# STM32F334x register map
File version: 1.1
Registers are 32-bit, read-write, reset 0x0 unless marked. A register's access mark holds for its fields unless they carry their own. Offsets are from the block's base; [hi:lo] are bit positions; {n}, {i} and the like mark numbered series.

## HRTIM_Master — High Resolution Timer: Master Timers
Base 0x40017400
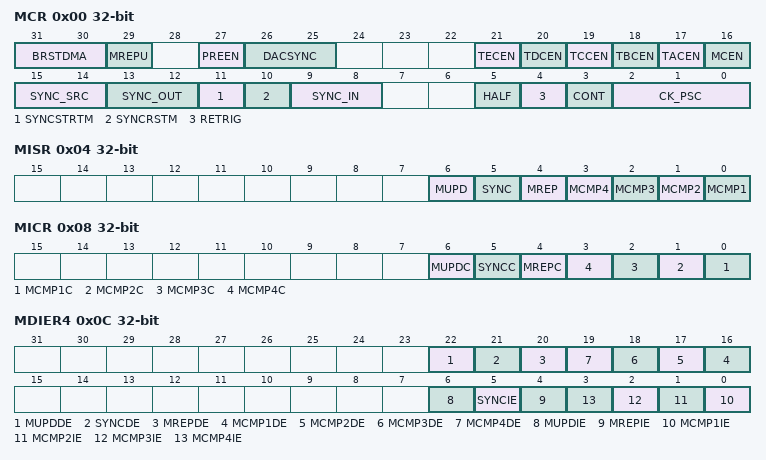
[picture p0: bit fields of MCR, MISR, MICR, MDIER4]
0x00 MCR — Master Timer Control Register
  [31:30] BRSTDMA — Burst DMA Update
  [29] MREPU — Master Timer Repetition update
  [27] PREEN — Preload enable
  [26:25] DACSYNC — AC Synchronization
  [21] TECEN — Timer E counter enable
  [20] TDCEN — Timer D counter enable
  [19] TCCEN — Timer C counter enable
  [18] TBCEN — Timer B counter enable
  [17] TACEN — Timer A counter enable
  [16] MCEN — Master Counter enable
  [15:14] SYNC_SRC — Synchronization source
  [13:12] SYNC_OUT — Synchronization output
  [11] SYNCSTRTM — Synchronization Starts Master
  [10] SYNCRSTM — Synchronization Resets Master
  [9:8] SYNC_IN — ynchronization input
  [5] HALF — Half mode enable
  [4] RETRIG — Master Re-triggerable mode
  [3] CONT — Master Continuous mode
  [2:0] CK_PSC — HRTIM Master Clock prescaler
0x04 MISR ro — Master Timer Interrupt Status Register
  [6] MUPD — Master Update Interrupt Flag
  [5] SYNC — Sync Input Interrupt Flag
  [4] MREP — Master Repetition Interrupt Flag
  [n-1] MCMP{n} (n=1..4) — Master Compare {n} Interrupt Flag
0x08 MICR wo — Master Timer Interrupt Clear Register
  [6] MUPDC — Master update Interrupt flag clear
  [5] SYNCC — Sync Input Interrupt flag clear
  [4] MREPC — Repetition Interrupt flag clear
  [n-1] MCMP{n}C (n=1..4) — Master Compare {n} Interrupt flag clear
0x0C MDIER4
  [22] MUPDDE, [21] SYNCDE, [20] MREPDE, [n+15] MCMP{n}DE (n=1..4), [6] MUPDIE, [5] SYNCIE, [4] MREPIE, [n-1] MCMP{n}IE (n=1..4)
0x10 MCNTR — Master Timer Counter Register
  [15:0] MCNT — Counter value
0x14 MPER reset 0xFFFF — Master Timer Period Register
  [15:0] MPER — Master Timer Period value
0x18 MREP — Master Timer Repetition Register
  [7:0] MREP — Master Timer Repetition counter value
0x1C MCMP1R — Master Timer Compare 1 Register
  [15:0] MCMP1 — Master Timer Compare 1 value
{0x1C+4i} MCMP{i}R (i=2..4) — Master Timer Compare {i} Register
  [15:0] MCMP{i} — Master Timer Compare {i} value

## ADC1 — Analog-to-Digital Converter
Base 0x50000000
Same registers: ADC2 0x50000100
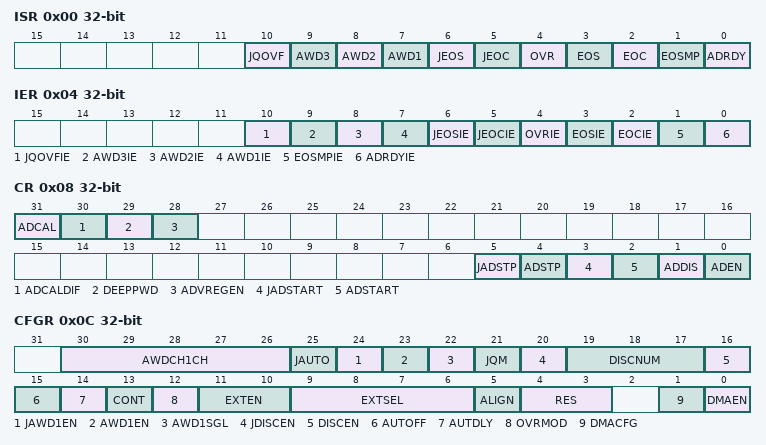
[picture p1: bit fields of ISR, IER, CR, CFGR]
0x00 ISR — interrupt and status register
  [10] JQOVF, [9] AWD3, [8] AWD2, [7] AWD1, [6] JEOS, [5] JEOC, [4] OVR, [3] EOS, [2] EOC, [1] EOSMP, [0] ADRDY
0x04 IER — interrupt enable register
  [10] JQOVFIE, [9] AWD3IE, [8] AWD2IE, [7] AWD1IE, [6] JEOSIE, [5] JEOCIE, [4] OVRIE, [3] EOSIE, [2] EOCIE, [1] EOSMPIE, [0] ADRDYIE
0x08 CR — control register
  [31] ADCAL, [30] ADCALDIF, [29] DEEPPWD, [28] ADVREGEN, [5] JADSTP, [4] ADSTP, [3] JADSTART, [2] ADSTART, [1] ADDIS, [0] ADEN
0x0C CFGR — configuration register
  [30:26] AWDCH1CH, [25] JAUTO, [24] JAWD1EN, [23] AWD1EN, [22] AWD1SGL, [21] JQM, [20] JDISCEN, [19:17] DISCNUM, [16] DISCEN, [15] AUTOFF, [14] AUTDLY, [13] CONT, [12] OVRMOD, [11:10] EXTEN, [9:6] EXTSEL, [5] ALIGN, [4:3] RES, [1] DMACFG, [0] DMAEN
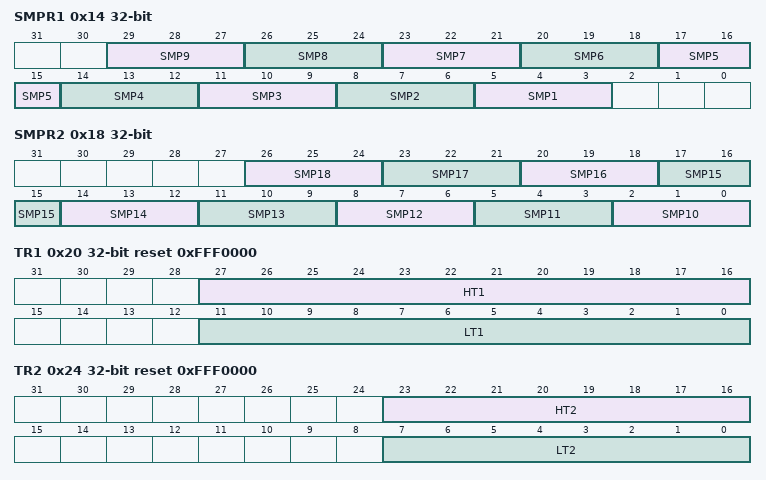
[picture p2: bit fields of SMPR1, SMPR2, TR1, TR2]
0x14 SMPR1 — sample time register 1
  [3n+2:3n] SMP{n} (n=1..9)
0x18 SMPR2 — sample time register 2
  [3n-28:3n-30] SMP{n} (n=10..18)
0x20 TR1 reset 0xFFF0000 — watchdog threshold register 1
  [27:16] HT1, [11:0] LT1
0x24 TR2 reset 0xFFF0000 — watchdog threshold register
  [23:16] HT2, [7:0] LT2
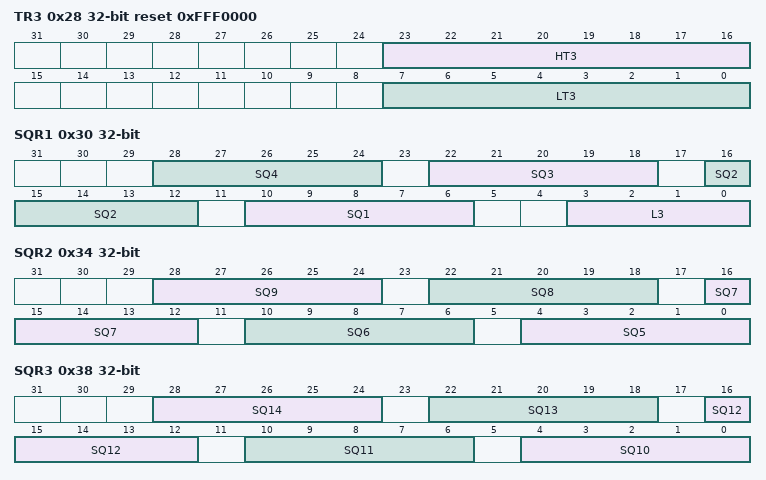
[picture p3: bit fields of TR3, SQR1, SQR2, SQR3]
0x28 TR3 reset 0xFFF0000 — watchdog threshold register 3
  [23:16] HT3, [7:0] LT3
0x30 SQR1 — regular sequence register 1
  [6n+4:6n] SQ{n} (n=1..4), [3:0] L3
0x34 SQR2 — regular sequence register 2
  [6n-26:6n-30] SQ{n} (n=5..9)
0x38 SQR3 — regular sequence register 3
  [6n-56:6n-60] SQ{n} (n=10..14)
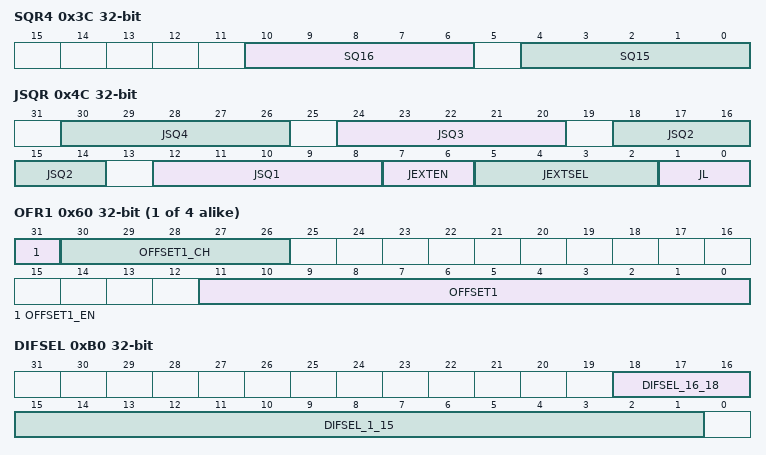
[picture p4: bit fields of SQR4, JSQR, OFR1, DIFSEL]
0x3C SQR4 — regular sequence register 4
  [10:6] SQ16, [4:0] SQ15
0x40 DR ro — regular Data Register
  [15:0] regularDATA
0x4C JSQR — injected sequence register
  [6n+6:6n+2] JSQ{n} (n=1..4), [7:6] JEXTEN, [5:2] JEXTSEL, [1:0] JL
{0x5C+4i} OFR{i} (i=1..4) — offset register {i}
  [31] OFFSET{i}_EN, [30:26] OFFSET{i}_CH, [11:0] OFFSET{i}
{0x7C+4i} JDR{i} ro (i=1..4) — injected data register {i}
  [15:0] JDATA{i}
0xA0 AWD2CR — Analog Watchdog 2 Configuration Register
  [18:1] AWD2CH
0xA4 AWD3CR — Analog Watchdog 3 Configuration Register
  [18:1] AWD3CH
0xB0 DIFSEL access per field — Differential Mode Selection Register 2
  [18:16] DIFSEL_16_18 ro — Differential mode for channels 18 to 16
  [15:1] DIFSEL_1_15 rw — Differential mode for channels 15 to 1
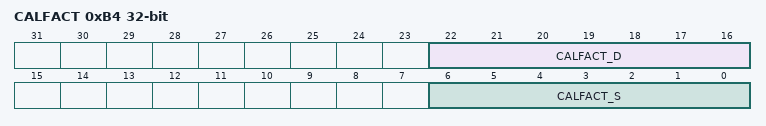
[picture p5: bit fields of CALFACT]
0xB4 CALFACT — Calibration Factors
  [22:16] CALFACT_D, [6:0] CALFACT_S

## ADC1_2 — Analog-to-Digital Converter
Base 0x50000300
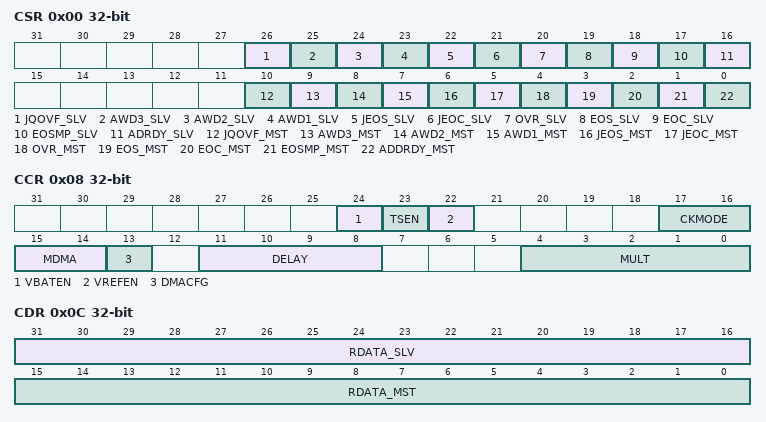
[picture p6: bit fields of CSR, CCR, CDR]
0x00 CSR ro — ADC Common status register
  [26] JQOVF_SLV — Injected Context Queue Overflow flag of the slave ADC
  [25] AWD3_SLV — Analog watchdog 3 flag of the slave ADC
  [24] AWD2_SLV — Analog watchdog 2 flag of the slave ADC
  [23] AWD1_SLV — Analog watchdog 1 flag of the slave ADC
  [22] JEOS_SLV — End of injected sequence flag of the slave ADC
  [21] JEOC_SLV — End of injected conversion flag of the slave ADC
  [20] OVR_SLV — Overrun flag of the slave ADC
  [19] EOS_SLV — End of regular sequence flag of the slave ADC
  [18] EOC_SLV — End of regular conversion of the slave ADC
  [17] EOSMP_SLV
  [16] ADRDY_SLV
  [10] JQOVF_MST
  [9] AWD3_MST
  [8] AWD2_MST
  [7] AWD1_MST
  [6] JEOS_MST
  [5] JEOC_MST
  [4] OVR_MST
  [3] EOS_MST
  [2] EOC_MST
  [1] EOSMP_MST
  [0] ADDRDY_MST
0x08 CCR — ADC common control register
  [24] VBATEN — VBAT enable
  [23] TSEN — Temperature sensor enable
  [22] VREFEN — VREFINT enable
  [17:16] CKMODE — ADC clock mode
  [15:14] MDMA — Direct memory access mode for multi ADC mode
  [13] DMACFG — DMA configuration (for multi-ADC mode)
  [11:8] DELAY — Delay between 2 sampling phases
  [4:0] MULT — Multi ADC mode selection
0x0C CDR ro — ADC common regular data register for dual and triple modes
  [31:16] RDATA_SLV — Regular data of the slave ADC
  [15:0] RDATA_MST — Regular data of the master ADC
